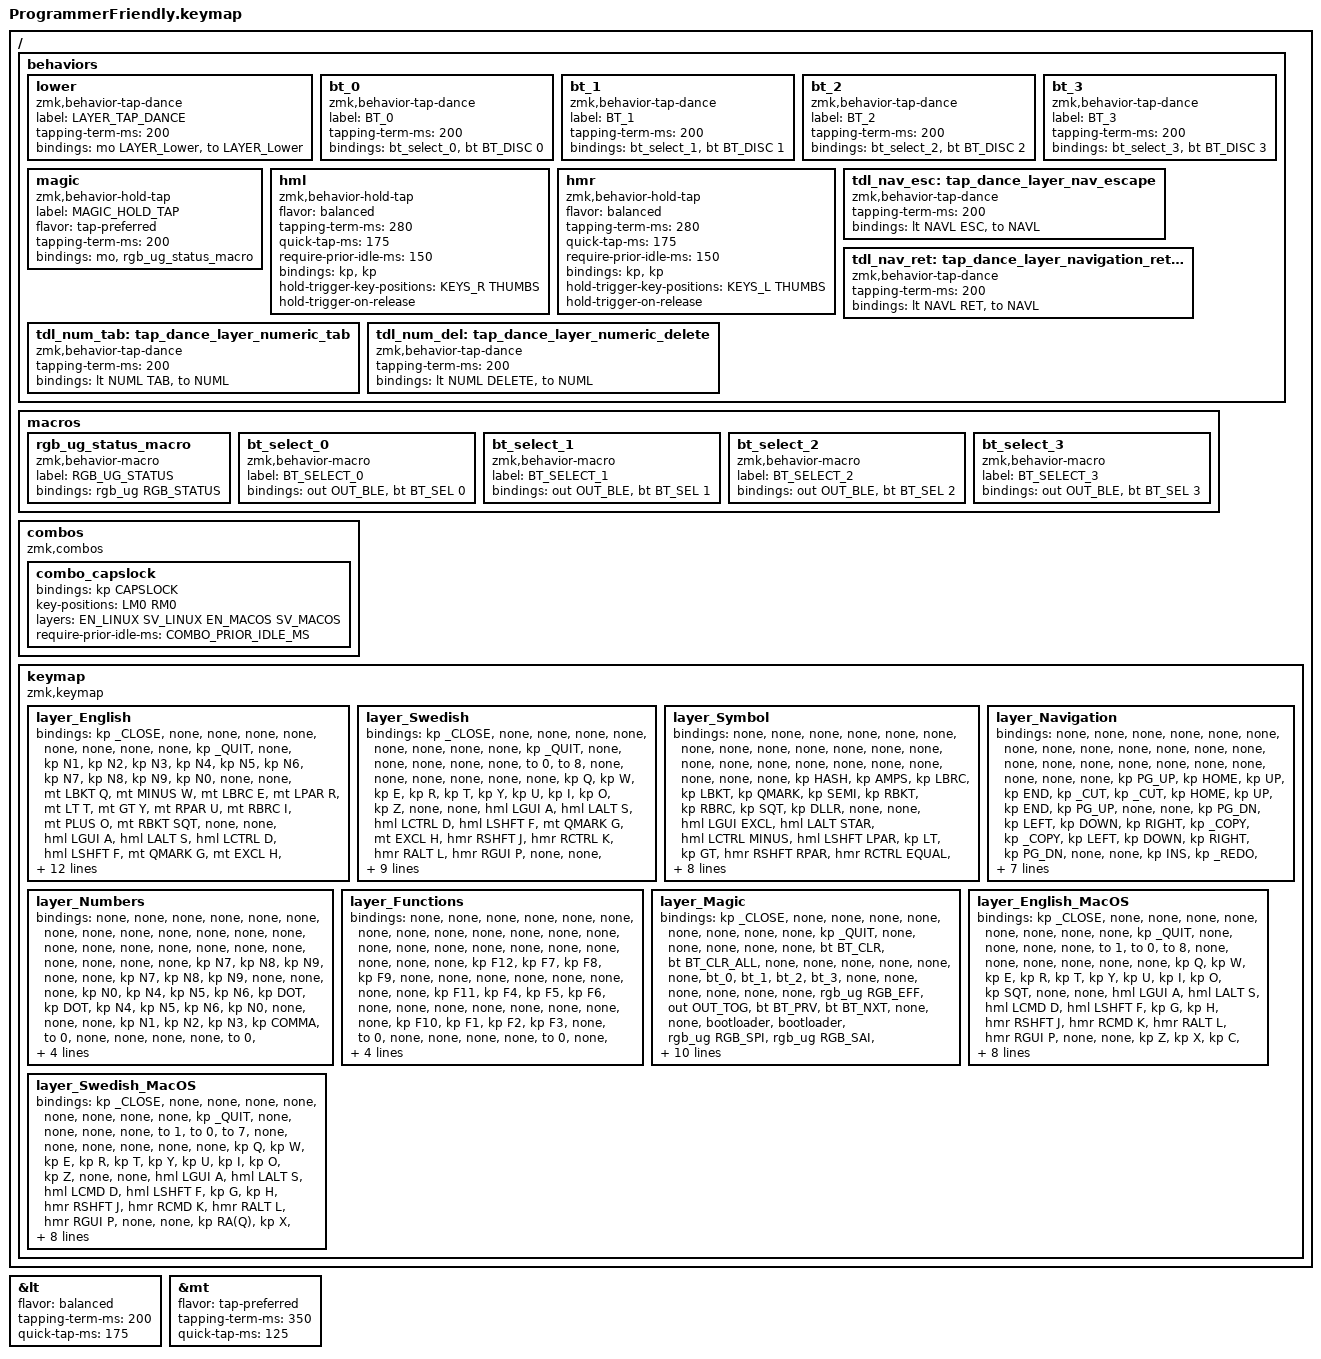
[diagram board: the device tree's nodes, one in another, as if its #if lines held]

/*
 * Copyright (c) 2020 The ZMK Contributors
 * Copyright (c) 2023 Innaworks Development Limited, trading as MoErgo
 *
 * SPDX-License-Identifier: MIT
 */


/* THIS FILE WAS GENERATED BY GLOVE80 LAYOUT EDITOR
 *
 * This file was generated automatically. You may or may not want to
 * edit it directly.
 */

#include <behaviors.dtsi>
/* Include all behavior includes needed */
#include <dt-bindings/zmk/outputs.h>
#include <dt-bindings/zmk/keys.h>
#include <dt-bindings/zmk/bt.h>
#include <dt-bindings/zmk/rgb.h>

/* Automatically generated layer name #define */
#define LAYER_English 0
#define LAYER_Swedish 1
#define LAYER_Symbol 2
#define LAYER_Navigation 3
#define LAYER_Numbers 4
#define LAYER_Functions 5
#define LAYER_Magic 6
#define LAYER_English_MacOS 7
#define LAYER_Swedish_MacOS 8

/* To deal with the situation where there is no Lower layer, to keep &lower happy */
#ifndef LAYER_Lower
#define LAYER_Lower 0
#endif

/* Custom Device-tree */



/* Glove80 system behavior & macros */
/ {
    behaviors {
        // For the "layer" key, it'd nice to be able to use it as either a shift or a toggle.
        // Configure it as a tap dance, so the first tap (or hold) is a &mo and the second tap is a &to
        lower: lower {
            compatible = "zmk,behavior-tap-dance";
            label = "LAYER_TAP_DANCE";
            #binding-cells = <0>;
            tapping-term-ms = <200>;
            bindings = <&mo LAYER_Lower>, <&to LAYER_Lower>;
        };
    };
};

/ {
    macros {
        rgb_ug_status_macro: rgb_ug_status_macro {
            label = "RGB_UG_STATUS";
            compatible = "zmk,behavior-macro";
            #binding-cells = <0>;
            bindings
                = <&rgb_ug RGB_STATUS>;
        };
    };
};


/ {
#ifdef BT_DISC_CMD
    behaviors {
        bt_0: bt_0 {
            compatible = "zmk,behavior-tap-dance";
            label = "BT_0";
            #binding-cells = <0>;
            tapping-term-ms = <200>;
            bindings = <&bt_select_0>, <&bt BT_DISC 0>;
        };
        bt_1: bt_1 {
            compatible = "zmk,behavior-tap-dance";
            label = "BT_1";
            #binding-cells = <0>;
            tapping-term-ms = <200>;
            bindings = <&bt_select_1>, <&bt BT_DISC 1>;
        };
        bt_2: bt_2 {
            compatible = "zmk,behavior-tap-dance";
            label = "BT_2";
            #binding-cells = <0>;
            tapping-term-ms = <200>;
            bindings = <&bt_select_2>, <&bt BT_DISC 2>;
        };
        bt_3: bt_3 {
            compatible = "zmk,behavior-tap-dance";
            label = "BT_3";
            #binding-cells = <0>;
            tapping-term-ms = <200>;
            bindings = <&bt_select_3>, <&bt BT_DISC 3>;
        };
    };
    macros {
        bt_select_0: bt_select_0 {
            label = "BT_SELECT_0";
            compatible = "zmk,behavior-macro";
            #binding-cells = <0>;
            bindings
                = <&out OUT_BLE>,
                  <&bt BT_SEL 0>;
        };
        bt_select_1: bt_select_1 {
            label = "BT_SELECT_1";
            compatible = "zmk,behavior-macro";
            #binding-cells = <0>;
            bindings
                = <&out OUT_BLE>,
                  <&bt BT_SEL 1>;
        };
        bt_select_2: bt_select_2 {
            label = "BT_SELECT_2";
            compatible = "zmk,behavior-macro";
            #binding-cells = <0>;
            bindings
                = <&out OUT_BLE>,
                  <&bt BT_SEL 2>;
        };
        bt_select_3: bt_select_3 {
            label = "BT_SELECT_3";
            compatible = "zmk,behavior-macro";
            #binding-cells = <0>;
            bindings
                = <&out OUT_BLE>,
                  <&bt BT_SEL 3>;
        };
    };
#else
    macros {
        bt_0: bt_0 {
            label = "BT_0";
            compatible = "zmk,behavior-macro";
            #binding-cells = <0>;
            bindings
                = <&out OUT_BLE>,
                  <&bt BT_SEL 0>;
        };
        bt_1: bt_1 {
            label = "BT_1";
            compatible = "zmk,behavior-macro";
            #binding-cells = <0>;
            bindings
                = <&out OUT_BLE>,
                  <&bt BT_SEL 1>;
        };
        bt_2: bt_2 {
            label = "BT_2";
            compatible = "zmk,behavior-macro";
            #binding-cells = <0>;
            bindings
                = <&out OUT_BLE>,
                  <&bt BT_SEL 2>;
        };
        bt_3: bt_3 {
            label = "BT_3";
            compatible = "zmk,behavior-macro";
            #binding-cells = <0>;
            bindings
                = <&out OUT_BLE>,
                  <&bt BT_SEL 3>;
        };
    };
#endif
};

/ {
    behaviors {
        magic: magic {
            compatible = "zmk,behavior-hold-tap";
            label = "MAGIC_HOLD_TAP";
            #binding-cells = <2>;
            flavor = "tap-preferred";
            tapping-term-ms = <200>;
            bindings = <&mo>, <&rgb_ug_status_macro>;
        };
    };
};

/* #define for key positions */
#define POS_LH_T1 52
#define POS_LH_T2 53
#define POS_LH_T3 54
#define POS_LH_T4 69
#define POS_LH_T5 70
#define POS_LH_T6 71
#define POS_LH_C1R2 15
#define POS_LH_C1R3 27
#define POS_LH_C1R4 39
#define POS_LH_C1R5 51
#define POS_LH_C2R1 4
#define POS_LH_C2R2 14
#define POS_LH_C2R3 26
#define POS_LH_C2R4 38
#define POS_LH_C2R5 50
#define POS_LH_C2R6 68
#define POS_LH_C3R1 3
#define POS_LH_C3R2 13
#define POS_LH_C3R3 25
#define POS_LH_C3R4 37
#define POS_LH_C3R5 49
#define POS_LH_C3R6 67
#define POS_LH_C4R1 2
#define POS_LH_C4R2 12
#define POS_LH_C4R3 24
#define POS_LH_C4R4 36
#define POS_LH_C4R5 48
#define POS_LH_C4R6 66
#define POS_LH_C5R1 1
#define POS_LH_C5R2 11
#define POS_LH_C5R3 23
#define POS_LH_C5R4 35
#define POS_LH_C5R5 47
#define POS_LH_C5R6 65
#define POS_LH_C6R1 0
#define POS_LH_C6R2 10
#define POS_LH_C6R3 22
#define POS_LH_C6R4 34
#define POS_LH_C6R5 46
#define POS_LH_C6R6 64
#define POS_RH_T1 57
#define POS_RH_T2 56
#define POS_RH_T3 55
#define POS_RH_T4 74
#define POS_RH_T5 73
#define POS_RH_T6 72
#define POS_RH_C1R2 16
#define POS_RH_C1R3 28
#define POS_RH_C1R4 40
#define POS_RH_C1R5 58
#define POS_RH_C2R1 5
#define POS_RH_C2R2 17
#define POS_RH_C2R3 29
#define POS_RH_C2R4 41
#define POS_RH_C2R5 59
#define POS_RH_C2R6 75
#define POS_RH_C3R1 6
#define POS_RH_C3R2 18
#define POS_RH_C3R3 30
#define POS_RH_C3R4 42
#define POS_RH_C3R5 60
#define POS_RH_C3R6 76
#define POS_RH_C4R1 7
#define POS_RH_C4R2 19
#define POS_RH_C4R3 31
#define POS_RH_C4R4 43
#define POS_RH_C4R5 61
#define POS_RH_C4R6 77
#define POS_RH_C5R1 8
#define POS_RH_C5R2 20
#define POS_RH_C5R3 32
#define POS_RH_C5R4 44
#define POS_RH_C5R5 62
#define POS_RH_C5R6 78
#define POS_RH_C6R1 9
#define POS_RH_C6R2 21
#define POS_RH_C6R3 33
#define POS_RH_C6R4 45
#define POS_RH_C6R5 63
#define POS_RH_C6R6 79

/* Custom Defined Behaviors */
/ {
/* GLOVE80 KEY MATRIX / LAYOUT MAPPING
 ╭────────────────────╮       ╭────────────────────╮
 │  0   1   2   3   4 ╰───┬───╯  5   6   7   8   9 │
 │ 10  11  12  13  14  15 │ 16  17  18  19  20  21 │
 │ 22  23  24  25  26  27 │ 28  29  30  31  32  33 │
 │ 34  35  36  37  38  39 │ 40  41  42  43  44  45 │
 │ 46  47  48  49  50  51 │ 58  59  60  61  62  63 │
 │ 64  65  66  67  68 ╭───┴───╮ 75  76  77  78  79 │
 ╰───────────┬────────┴───┬───┴────────┬───────────╯
             │ 52  53  54 │ 55  56  57 │
             │ 69  70  71 │ 72  73  74 │
             ╰────────────┴────────────╯

 ╭────────────────────╮       ╭────────────────────╮
 │ LC5 LC4 LC3 LC2 LC1╰───┬───╯ RC1 RC2 RC3 RC4 RC5│
 │ LN5 LN4 LN3 LN2 LN1 LN0│ RN0 RN1 RN2 RN3 RN4 RN5│
 │ LT5 LT4 LT3 LT2 LT1 LT0│ RT0 RT1 RT2 RT3 RT4 RT5│
 │ LM5 LM4 LM3 LM2 LM1 LM0│ RM0 RM1 RM2 RM3 RM4 RM5│
 │ LB5 LB4 LB3 LB2 LB1 LB0│ RB0 RB1 RB2 RB3 RB4 RB5│
 │ LF5 LF4 LF3 LF2 LF1╭───┴───╮ RF1 RF2 RF3 RF4 RF5│
 ╰───────────┬────────┴───┬───┴────────┬───────────╯
             │ LH5 LH4 LH3│ RH3 RH4 RH5│
             │ LH2 LH1 LH0│ RH0 RH1 RH2│
             ╰────────────┴────────────╯

 C : Ceiling
 N : Number
 T : Top
 M : Middle
 B : Bottom
 F : Floor
*/

#define LC1  4  // left-ceiling row
#define LC2  3
#define LC3  2
#define LC4  1
#define LC5  0

#define RC1  5  // right-ceiling row
#define RC2  6
#define RC3  7
#define RC4  8
#define RC5  9

#define LN0 15  // left-number row
#define LN1 14
#define LN2 13
#define LN3 12
#define LN4 11
#define LN5 10

#define RN0 16  // right-number row
#define RN1 17
#define RN2 18
#define RN3 19
#define RN4 20
#define RN5 21

#define LT0 27  // left-top row
#define LT1 26
#define LT2 25
#define LT3 24
#define LT4 23
#define LT5 22

#define RT0 28  // right-top row
#define RT1 29
#define RT2 30
#define RT3 31
#define RT4 32
#define RT5 33

#define LM0 39  // left-middle row
#define LM1 38
#define LM2 37
#define LM3 36
#define LM4 35
#define LM5 34

#define RM0 40  // right-middle row
#define RM1 41
#define RM2 42
#define RM3 43
#define RM4 44
#define RM5 45

#define LB0 51  // left-bottom row
#define LB1 50
#define LB2 49
#define LB3 48
#define LB4 47
#define LB5 46

#define RB0 58  // right-bottom row
#define RB1 59
#define RB2 60
#define RB3 61
#define RB4 62
#define RB5 63

#define LF1 68  // left-floor row
#define LF2 67
#define LF3 66
#define LF4 65
#define LF5 64

#define RF1 75  // right-floor row
#define RF2 76
#define RF3 77
#define RF4 78
#define RF5 79

#define LH0 71  // left thumb keys
#define LH1 70
#define LH2 69
#define LH3 54
#define LH4 53
#define LH5 52

#define RH0 72  // right thumb keys
#define RH1 73
#define RH2 74
#define RH3 55
#define RH4 56
#define RH5 57

#define KEYS_L              \
    LC5 LC4 LC3 LC2 LC1     \
    LN5 LN4 LN3 LN2 LN1 LN0 \
    LT5 LT4 LT3 LT2 LT1 LT0 \
    LM5 LM4 LM3 LM2 LM1 LM0 \
    LB5 LB4 LB3 LB2 LB1 LB0 \
    LF5 LF4 LF3 LF2 LF1
#define KEYS_R              \
        RC1 RC2 RC3 RC4 RC5 \
    RN0 RN1 RN2 RN3 RN4 RN5 \
    RT0 RT1 RT2 RT3 RT4 RT5 \
    RM0 RM1 RM2 RM3 RM4 RM5 \
    RB0 RB1 RB2 RB3 RB4 RB5 \
        RF1 RF2 RF3 RF4 RF5
#define THUMBS              \
    LH5 LH4 LH3 RH3 RH4 RH5 \
    LH2 LH1 LH0 RH0 RH1 RH2

#define EN_LINUX    0
#define SV_LINUX    1
#define SYML        2 // Symbols
#define NAVL        3 // Navigation
#define NUML        4 // Numeric
#define FUNL        5 // Functions
#define SYSL        6 // System/Settings
#define EN_MACOS    7
#define SV_MACOS    8

#define OS_MAC   1
#define OS_WIN   2
#define OS_LINUX 3

#define TARGET_OS OS_LINUX

#if TARGET_OS == OS_MAC
#   define _C LG
#   define _QUIT _C(Q)
#   define _APP_NXT LG(TAB)
#   define _APP_PRV LS(LG(TAB))
#   define _WIN_NXT LG(GRAVE)
#   define _WIN_PRV LS(LG(GRAVE))
#   define _LOCK_SCR   LC(LG(Q))
#else
#   define _C LC
#   define _QUIT LA(F4)
#   define _APP_NXT LA(TAB)
#   define _APP_PRV LS(LA(TAB))
#   define _WIN_NXT LC(TAB)
#   define _WIN_PRV LS(LC(TAB))
#   define _LOCK_SCR LC(LG(Q))
#endif

#define _CUT        _C(X)
#define _COPY       _C(C)
#define _PASTE      _C(V)
#define _UNDO       _C(Z)
#define _REDO       LS(_UNDO)
#define _SEL_ALL    _C(A)
#define _CLOSE      _C(W)


/*HACK*/};
&lt {
    flavor = "balanced";
    tapping-term-ms = <200>;
    quick-tap-ms = <175>;                // repeat on tap-into-hold
    //require-prior-idle-ms = <150>;
};

/* Override the default &mt settings to enable fast typing. Note that this config will cause unexpected behavior in other functionality that relies on the default &mt implementation.*/
&mt {
    flavor = "tap-preferred"; // the default is "hold-preferred", which is the exact opposite.
    tapping-term-ms = <350>;
    quick-tap-ms = <125>;
};
/*HACK*//{

behaviors {
    // left-hand HRMs
    hml: hml {
        compatible = "zmk,behavior-hold-tap";
        #binding-cells = <2>;
        flavor = "balanced";
        tapping-term-ms = <280>;
        quick-tap-ms = <175>;                // repeat on tap-into-hold
        require-prior-idle-ms = <150>;
        bindings = <&kp>, <&kp>;
        hold-trigger-key-positions = <KEYS_R THUMBS>;
        hold-trigger-on-release;             // delay positional check until key-release
    };

    // right-hand HRMs
    hmr: hmr {
        compatible = "zmk,behavior-hold-tap";
        #binding-cells = <2>;
        flavor = "balanced";
        tapping-term-ms = <280>;
        quick-tap-ms = <175>;                // repeat on tap-into-hold
        require-prior-idle-ms = <150>;
        bindings = <&kp>, <&kp>;
        hold-trigger-key-positions = <KEYS_L THUMBS>;
        hold-trigger-on-release;             // delay positional check until key-release
    };

    // Tap-dance and layer tap: one tap outputs a key press, two taps switches to layer, tap and hold enables the layer temporarily.
    tdl_nav_esc: tap_dance_layer_nav_escape {
        compatible = "zmk,behavior-tap-dance";
        #binding-cells = <0>;
        tapping-term-ms = <200>;
        bindings = <&lt NAVL ESC>, <&to NAVL>;
    };
    tdl_nav_ret: tap_dance_layer_navigation_return {
        compatible = "zmk,behavior-tap-dance";
        #binding-cells = <0>;
        tapping-term-ms = <200>;
        bindings = <&lt NAVL RET>, <&to NAVL>;
    };
    tdl_num_tab: tap_dance_layer_numeric_tab {
        compatible = "zmk,behavior-tap-dance";
        #binding-cells = <0>;
        tapping-term-ms = <200>;
        bindings = <&lt NUML TAB>, <&to NUML>;
    };
    tdl_num_del: tap_dance_layer_numeric_delete {
        compatible = "zmk,behavior-tap-dance";
        #binding-cells = <0>;
        tapping-term-ms = <200>;
        bindings = <&lt NUML DELETE>, <&to NUML>;
    };
};

#define COMBO_PRIOR_IDLE_MS 150
#define COMBO_TIMEOUT_MS 10

combos {
    compatible = "zmk,combos";

    // Both hand combos
    combo_capslock { // G + H -> Caps Lock
        bindings = <&kp CAPSLOCK>;
        key-positions = <LM0 RM0>;
        layers = <EN_LINUX SV_LINUX EN_MACOS SV_MACOS>;
        require-prior-idle-ms = <COMBO_PRIOR_IDLE_MS>;
        //timeout-ms = <COMBO_TIMEOUT_MS>;
    };
};
};

/* Automatically generated macro definitions */
/ {
    macros {
    
    };
};

/* Automatically generated keymap */
/ {
    keymap {
        compatible = "zmk,keymap";


        layer_English {
            bindings = <
              // Row 1 Left
              /* F1    */ &kp _CLOSE
              /* F2    */ &none
              /* F3    */ &none
              /* F4    */ &none
              /* F5    */ &none
              // Row 1 Right
              /* F6    */ &none
              /* F7    */ &none
              /* F8    */ &none
              /* F9    */ &none
              /* F10   */ &kp _QUIT
              // Row 2 Left
              /* EQUAL */ &none
              /* 1     */ &kp N1
              /* 2     */ &kp N2
              /* 3     */ &kp N3
              /* 4     */ &kp N4
              /* 5     */ &kp N5
              // Row 2 Right
              /* 6     */ &kp N6
              /* 7     */ &kp N7
              /* 8     */ &kp N8
              /* 9     */ &kp N9
              /* 0     */ &kp N0
              /* MINUS */ &none
              // Row 3 Left
              /* TAB   */ &none
              /* Q     */ &mt LBKT Q
              /* W     */ &mt MINUS W
              /* E     */ &mt LBRC E
              /* R     */ &mt LPAR R
              /* T     */ &mt LT T
              // Row 3 Right
              /* Y     */ &mt GT Y
              /* U     */ &mt RPAR U
              /* I     */ &mt RBRC I
              /* O     */ &mt PLUS O
              /* P     */ &mt RBKT SQT
              /* BSLSH */ &none
              // Row 4 Left
              /* ESC   */ &none
              /* A     */ &hml LGUI A
              /* S     */ &hml LALT S
              /* D     */ &hml LCTRL D
              /* F     */ &hml LSHFT F
              /* G     */ &mt QMARK G
              // Row 4 Right
              /* H     */ &mt EXCL H
              /* J     */ &hmr RSHFT J
              /* K     */ &hmr RCTRL K
              /* L     */ &hmr RALT L
              /* SEMI  */ &hmr RGUI P
              /* SQUOT */ &none
              // Row 5 Left
              /* BQUOT */ &none
              /* Z     */ &mt STAR Z
              /* X     */ &mt UNDER X
              /* C     */ &mt AT C
              /* V     */ &mt EQUAL V
              /* B     */ &mt PIPE B
              // Row 5 Thumb
              /* LSHFT */ &tdl_num_del
              /* LCTRL */ &kp C_PREV
              /* LOWER */ &kp C_NEXT
              /* LGUI  */ &kp C_VOL_DN
              /* RCTRL */ &lt 5 C_VOL_UP
              /* RSHFT */ &tdl_num_tab
              // Row 5 Right
              /* N     */ &mt AMPS N
              /* M     */ &mt DQT M
              /* COMMA */ &mt SEMI COMMA
              /* DOT   */ &mt COLON DOT
              /* FSLSH */ &mt BSLH FSLH
              /* PGUP  */ &none
              // Row 6 Left
              /* MAGIC */ &magic LAYER_Magic 0
              /* HOME  */ &to 1
              /* END   */ &kp LGUI
              /* LEFT  */ &kp LALT
              /* RIGHT */ &kp LSHFT
              // Row 6 Thumb
              /* BKSP  */ &lt 2 BSPC
              /* DEL   */ &tdl_nav_esc
              /* LALT  */ &kp C_PP
              /* RALT  */ &kp C_MUTE
              /* ENTER */ &tdl_nav_ret
              /* SPACE */ &lt 2 SPACE
              // Row 6 Right
              /* UP    */ &kp RSHFT
              /* DOWN  */ &kp RALT
              /* LBRKT */ &kp RGUI
              /* RBRKT */ &to 7
              /* PGDN  */ &magic LAYER_Magic 0
            >;
        };

        layer_Swedish {
            bindings = <
              // Row 1 Left
              /* F1    */ &kp _CLOSE
              /* F2    */ &none
              /* F3    */ &none
              /* F4    */ &none
              /* F5    */ &none
              // Row 1 Right
              /* F6    */ &none
              /* F7    */ &none
              /* F8    */ &none
              /* F9    */ &none
              /* F10   */ &kp _QUIT
              // Row 2 Left
              /* EQUAL */ &none
              /* 1     */ &none
              /* 2     */ &none
              /* 3     */ &none
              /* 4     */ &none
              /* 5     */ &to 0
              // Row 2 Right
              /* 6     */ &to 8
              /* 7     */ &none
              /* 8     */ &none
              /* 9     */ &none
              /* 0     */ &none
              /* MINUS */ &none
              // Row 3 Left
              /* TAB   */ &none
              /* Q     */ &kp Q
              /* W     */ &kp W
              /* E     */ &kp E
              /* R     */ &kp R
              /* T     */ &kp T
              // Row 3 Right
              /* Y     */ &kp Y
              /* U     */ &kp U
              /* I     */ &kp I
              /* O     */ &kp O
              /* P     */ &kp Z
              /* BSLSH */ &none
              // Row 4 Left
              /* ESC   */ &none
              /* A     */ &hml LGUI A
              /* S     */ &hml LALT S
              /* D     */ &hml LCTRL D
              /* F     */ &hml LSHFT F
              /* G     */ &mt QMARK G
              // Row 4 Right
              /* H     */ &mt EXCL H
              /* J     */ &hmr RSHFT J
              /* K     */ &hmr RCTRL K
              /* L     */ &hmr RALT L
              /* SEMI  */ &hmr RGUI P
              /* SQUOT */ &none
              // Row 5 Left
              /* BQUOT */ &none
              /* Z     */ &kp RA(Q)
              /* X     */ &kp X
              /* C     */ &kp C
              /* V     */ &kp V
              /* B     */ &kp B
              // Row 5 Thumb
              /* LSHFT */ &tdl_num_del
              /* LCTRL */ &kp C_PREV
              /* LOWER */ &kp C_NEXT
              /* LGUI  */ &kp C_VOL_DN
              /* RCTRL */ &lt 5 C_VOL_UP
              /* RSHFT */ &tdl_num_tab
              // Row 5 Right
              /* N     */ &kp N
              /* M     */ &mt DQT M
              /* COMMA */ &kp COMMA
              /* DOT   */ &kp DOT
              /* FSLSH */ &kp RA(P)
              /* PGUP  */ &none
              // Row 6 Left
              /* MAGIC */ &magic LAYER_Magic 0
              /* HOME  */ &none
              /* END   */ &kp LGUI
              /* LEFT  */ &kp LALT
              /* RIGHT */ &kp LSHFT
              // Row 6 Thumb
              /* BKSP  */ &lt 2 BSPC
              /* DEL   */ &tdl_nav_esc
              /* LALT  */ &kp C_PP
              /* RALT  */ &kp C_MUTE
              /* ENTER */ &tdl_nav_ret
              /* SPACE */ &lt 2 SPACE
              // Row 6 Right
              /* UP    */ &kp RSHFT
              /* DOWN  */ &kp RALT
              /* LBRKT */ &kp RGUI
              /* RBRKT */ &none
              /* PGDN  */ &magic LAYER_Magic 0
            >;
        };

        layer_Symbol {
            bindings = <
              // Row 1 Left
              /* F1    */ &none
              /* F2    */ &none
              /* F3    */ &none
              /* F4    */ &none
              /* F5    */ &none
              // Row 1 Right
              /* F6    */ &none
              /* F7    */ &none
              /* F8    */ &none
              /* F9    */ &none
              /* F10   */ &none
              // Row 2 Left
              /* EQUAL */ &none
              /* 1     */ &none
              /* 2     */ &none
              /* 3     */ &none
              /* 4     */ &none
              /* 5     */ &none
              // Row 2 Right
              /* 6     */ &none
              /* 7     */ &none
              /* 8     */ &none
              /* 9     */ &none
              /* 0     */ &none
              /* MINUS */ &none
              // Row 3 Left
              /* TAB   */ &none
              /* Q     */ &kp HASH
              /* W     */ &kp AMPS
              /* E     */ &kp LBRC
              /* R     */ &kp LBKT
              /* T     */ &kp QMARK
              // Row 3 Right
              /* Y     */ &kp SEMI
              /* U     */ &kp RBKT
              /* I     */ &kp RBRC
              /* O     */ &kp SQT
              /* P     */ &kp DLLR
              /* BSLSH */ &none
              // Row 4 Left
              /* ESC   */ &none
              /* A     */ &hml LGUI EXCL
              /* S     */ &hml LALT STAR
              /* D     */ &hml LCTRL MINUS
              /* F     */ &hml LSHFT LPAR
              /* G     */ &kp LT
              // Row 4 Right
              /* H     */ &kp GT
              /* J     */ &hmr RSHFT RPAR
              /* K     */ &hmr RCTRL EQUAL
              /* L     */ &hmr RALT DOUBLE_QUOTES
              /* SEMI  */ &hmr RGUI SLASH
              /* SQUOT */ &none
              // Row 5 Left
              /* BQUOT */ &none
              /* Z     */ &kp TILDE
              /* X     */ &kp PRCNT
              /* C     */ &kp PLUS
              /* V     */ &kp PIPE
              /* B     */ &kp COLON
              // Row 5 Thumb
              /* LSHFT */ &kp LALT
              /* LCTRL */ &none
              /* LOWER */ &none
              /* LGUI  */ &none
              /* RCTRL */ &none
              /* RSHFT */ &kp RALT
              // Row 5 Right
              /* N     */ &kp QMARK
              /* M     */ &kp UNDER
              /* COMMA */ &kp AT
              /* DOT   */ &kp GRAVE
              /* FSLSH */ &kp BSLH
              /* PGUP  */ &none
              // Row 6 Left
              /* MAGIC */ &magic LAYER_Magic 0
              /* HOME  */ &none
              /* END   */ &none
              /* LEFT  */ &none
              /* RIGHT */ &none
              // Row 6 Thumb
              /* BKSP  */ &to 0
              /* DEL   */ &none
              /* LALT  */ &none
              /* RALT  */ &none
              /* ENTER */ &none
              /* SPACE */ &to 0
              // Row 6 Right
              /* UP    */ &none
              /* DOWN  */ &none
              /* LBRKT */ &none
              /* RBRKT */ &none
              /* PGDN  */ &none
            >;
        };

        layer_Navigation {
            bindings = <
              // Row 1 Left
              /* F1    */ &none
              /* F2    */ &none
              /* F3    */ &none
              /* F4    */ &none
              /* F5    */ &none
              // Row 1 Right
              /* F6    */ &none
              /* F7    */ &none
              /* F8    */ &none
              /* F9    */ &none
              /* F10   */ &none
              // Row 2 Left
              /* EQUAL */ &none
              /* 1     */ &none
              /* 2     */ &none
              /* 3     */ &none
              /* 4     */ &none
              /* 5     */ &none
              // Row 2 Right
              /* 6     */ &none
              /* 7     */ &none
              /* 8     */ &none
              /* 9     */ &none
              /* 0     */ &none
              /* MINUS */ &none
              // Row 3 Left
              /* TAB   */ &none
              /* Q     */ &kp PG_UP
              /* W     */ &kp HOME
              /* E     */ &kp UP
              /* R     */ &kp END
              /* T     */ &kp _CUT
              // Row 3 Right
              /* Y     */ &kp _CUT
              /* U     */ &kp HOME
              /* I     */ &kp UP
              /* O     */ &kp END
              /* P     */ &kp PG_UP
              /* BSLSH */ &none
              // Row 4 Left
              /* ESC   */ &none
              /* A     */ &kp PG_DN
              /* S     */ &kp LEFT
              /* D     */ &kp DOWN
              /* F     */ &kp RIGHT
              /* G     */ &kp _COPY
              // Row 4 Right
              /* H     */ &kp _COPY
              /* J     */ &kp LEFT
              /* K     */ &kp DOWN
              /* L     */ &kp RIGHT
              /* SEMI  */ &kp PG_DN
              /* SQUOT */ &none
              // Row 5 Left
              /* BQUOT */ &none
              /* Z     */ &kp INS
              /* X     */ &kp _REDO
              /* C     */ &kp _SEL_ALL
              /* V     */ &kp _UNDO
              /* B     */ &kp _PASTE
              // Row 5 Thumb
              /* LSHFT */ &to 0
              /* LCTRL */ &none
              /* LOWER */ &none
              /* LGUI  */ &none
              /* RCTRL */ &none
              /* RSHFT */ &to 0
              // Row 5 Right
              /* N     */ &kp _PASTE
              /* M     */ &kp _UNDO
              /* COMMA */ &kp _REDO
              /* DOT   */ &kp _SEL_ALL
              /* FSLSH */ &kp INS
              /* PGUP  */ &none
              // Row 6 Left
              /* MAGIC */ &magic LAYER_Magic 0
              /* HOME  */ &none
              /* END   */ &none
              /* LEFT  */ &kp _WIN_PRV
              /* RIGHT */ &kp _WIN_NXT
              // Row 6 Thumb
              /* BKSP  */ &to 1
              /* DEL   */ &none
              /* LALT  */ &none
              /* RALT  */ &none
              /* ENTER */ &none
              /* SPACE */ &to 1
              // Row 6 Right
              /* UP    */ &kp _APP_PRV
              /* DOWN  */ &kp _APP_NXT
              /* LBRKT */ &none
              /* RBRKT */ &none
              /* PGDN  */ &none
            >;
        };

        layer_Numbers {
            bindings = <
              // Row 1 Left
              /* F1    */ &none
              /* F2    */ &none
              /* F3    */ &none
              /* F4    */ &none
              /* F5    */ &none
              // Row 1 Right
              /* F6    */ &none
              /* F7    */ &none
              /* F8    */ &none
              /* F9    */ &none
              /* F10   */ &none
              // Row 2 Left
              /* EQUAL */ &none
              /* 1     */ &none
              /* 2     */ &none
              /* 3     */ &none
              /* 4     */ &none
              /* 5     */ &none
              // Row 2 Right
              /* 6     */ &none
              /* 7     */ &none
              /* 8     */ &none
              /* 9     */ &none
              /* 0     */ &none
              /* MINUS */ &none
              // Row 3 Left
              /* TAB   */ &none
              /* Q     */ &none
              /* W     */ &kp N7
              /* E     */ &kp N8
              /* R     */ &kp N9
              /* T     */ &none
              // Row 3 Right
              /* Y     */ &none
              /* U     */ &kp N7
              /* I     */ &kp N8
              /* O     */ &kp N9
              /* P     */ &none
              /* BSLSH */ &none
              // Row 4 Left
              /* ESC   */ &none
              /* A     */ &kp N0
              /* S     */ &kp N4
              /* D     */ &kp N5
              /* F     */ &kp N6
              /* G     */ &kp DOT
              // Row 4 Right
              /* H     */ &kp DOT
              /* J     */ &kp N4
              /* K     */ &kp N5
              /* L     */ &kp N6
              /* SEMI  */ &kp N0
              /* SQUOT */ &none
              // Row 5 Left
              /* BQUOT */ &none
              /* Z     */ &none
              /* X     */ &kp N1
              /* C     */ &kp N2
              /* V     */ &kp N3
              /* B     */ &kp COMMA
              // Row 5 Thumb
              /* LSHFT */ &to 0
              /* LCTRL */ &none
              /* LOWER */ &none
              /* LGUI  */ &none
              /* RCTRL */ &none
              /* RSHFT */ &to 0
              // Row 5 Right
              /* N     */ &kp COMMA
              /* M     */ &kp N1
              /* COMMA */ &kp N2
              /* DOT   */ &kp N3
              /* FSLSH */ &none
              /* PGUP  */ &none
              // Row 6 Left
              /* MAGIC */ &magic LAYER_Magic 0
              /* HOME  */ &none
              /* END   */ &none
              /* LEFT  */ &none
              /* RIGHT */ &none
              // Row 6 Thumb
              /* BKSP  */ &to 1
              /* DEL   */ &none
              /* LALT  */ &none
              /* RALT  */ &none
              /* ENTER */ &none
              /* SPACE */ &to 1
              // Row 6 Right
              /* UP    */ &none
              /* DOWN  */ &none
              /* LBRKT */ &none
              /* RBRKT */ &none
              /* PGDN  */ &none
            >;
        };

        layer_Functions {
            bindings = <
              // Row 1 Left
              /* F1    */ &none
              /* F2    */ &none
              /* F3    */ &none
              /* F4    */ &none
              /* F5    */ &none
              // Row 1 Right
              /* F6    */ &none
              /* F7    */ &none
              /* F8    */ &none
              /* F9    */ &none
              /* F10   */ &none
              // Row 2 Left
              /* EQUAL */ &none
              /* 1     */ &none
              /* 2     */ &none
              /* 3     */ &none
              /* 4     */ &none
              /* 5     */ &none
              // Row 2 Right
              /* 6     */ &none
              /* 7     */ &none
              /* 8     */ &none
              /* 9     */ &none
              /* 0     */ &none
              /* MINUS */ &none
              // Row 3 Left
              /* TAB   */ &none
              /* Q     */ &kp F12
              /* W     */ &kp F7
              /* E     */ &kp F8
              /* R     */ &kp F9
              /* T     */ &none
              // Row 3 Right
              /* Y     */ &none
              /* U     */ &none
              /* I     */ &none
              /* O     */ &none
              /* P     */ &none
              /* BSLSH */ &none
              // Row 4 Left
              /* ESC   */ &none
              /* A     */ &kp F11
              /* S     */ &kp F4
              /* D     */ &kp F5
              /* F     */ &kp F6
              /* G     */ &none
              // Row 4 Right
              /* H     */ &none
              /* J     */ &none
              /* K     */ &none
              /* L     */ &none
              /* SEMI  */ &none
              /* SQUOT */ &none
              // Row 5 Left
              /* BQUOT */ &none
              /* Z     */ &kp F10
              /* X     */ &kp F1
              /* C     */ &kp F2
              /* V     */ &kp F3
              /* B     */ &none
              // Row 5 Thumb
              /* LSHFT */ &to 0
              /* LCTRL */ &none
              /* LOWER */ &none
              /* LGUI  */ &none
              /* RCTRL */ &none
              /* RSHFT */ &to 0
              // Row 5 Right
              /* N     */ &none
              /* M     */ &none
              /* COMMA */ &none
              /* DOT   */ &none
              /* FSLSH */ &none
              /* PGUP  */ &none
              // Row 6 Left
              /* MAGIC */ &magic LAYER_Magic 0
              /* HOME  */ &none
              /* END   */ &none
              /* LEFT  */ &none
              /* RIGHT */ &none
              // Row 6 Thumb
              /* BKSP  */ &to 1
              /* DEL   */ &none
              /* LALT  */ &none
              /* RALT  */ &none
              /* ENTER */ &none
              /* SPACE */ &to 1
              // Row 6 Right
              /* UP    */ &none
              /* DOWN  */ &none
              /* LBRKT */ &none
              /* RBRKT */ &none
              /* PGDN  */ &none
            >;
        };

        layer_Magic {
            bindings = <
              // Row 1 Left
              /* F1    */ &kp _CLOSE
              /* F2    */ &none
              /* F3    */ &none
              /* F4    */ &none
              /* F5    */ &none
              // Row 1 Right
              /* F6    */ &none
              /* F7    */ &none
              /* F8    */ &none
              /* F9    */ &none
              /* F10   */ &kp _QUIT
              // Row 2 Left
              /* EQUAL */ &none
              /* 1     */ &none
              /* 2     */ &none
              /* 3     */ &none
              /* 4     */ &none
              /* 5     */ &bt BT_CLR
              // Row 2 Right
              /* 6     */ &bt BT_CLR_ALL
              /* 7     */ &none
              /* 8     */ &none
              /* 9     */ &none
              /* 0     */ &none
              /* MINUS */ &none
              // Row 3 Left
              /* TAB   */ &none
              /* Q     */ &bt_0
              /* W     */ &bt_1
              /* E     */ &bt_2
              /* R     */ &bt_3
              /* T     */ &none
              // Row 3 Right
              /* Y     */ &none
              /* U     */ &none
              /* I     */ &none
              /* O     */ &none
              /* P     */ &none
              /* BSLSH */ &rgb_ug RGB_EFF
              // Row 4 Left
              /* ESC   */ &out OUT_TOG
              /* A     */ &bt BT_PRV
              /* S     */ &bt BT_NXT
              /* D     */ &none
              /* F     */ &none
              /* G     */ &bootloader
              // Row 4 Right
              /* H     */ &bootloader
              /* J     */ &rgb_ug RGB_SPI
              /* K     */ &rgb_ug RGB_SAI
              /* L     */ &rgb_ug RGB_HUI
              /* SEMI  */ &rgb_ug RGB_BRI
              /* SQUOT */ &rgb_ug RGB_TOG
              // Row 5 Left
              /* BQUOT */ &none
              /* Z     */ &none
              /* X     */ &none
              /* C     */ &none
              /* V     */ &none
              /* B     */ &sys_reset
              // Row 5 Thumb
              /* LSHFT */ &bt_2
              /* LCTRL */ &bt_3
              /* LOWER */ &none
              /* LGUI  */ &kp C_VOL_DN
              /* RCTRL */ &kp C_VOL_UP
              /* RSHFT */ &kp C_MUTE
              // Row 5 Right
              /* N     */ &sys_reset
              /* M     */ &rgb_ug RGB_SPD
              /* COMMA */ &rgb_ug RGB_SAD
              /* DOT   */ &rgb_ug RGB_HUD
              /* FSLSH */ &rgb_ug RGB_BRD
              /* PGUP  */ &rgb_ug RGB_EFR
              // Row 6 Left
              /* MAGIC */ &none
              /* HOME  */ &none
              /* END   */ &none
              /* LEFT  */ &none
              /* RIGHT */ &none
              // Row 6 Thumb
              /* BKSP  */ &bt_0
              /* DEL   */ &bt_1
              /* LALT  */ &out OUT_USB
              /* RALT  */ &kp C_PREV
              /* ENTER */ &kp C_NEXT
              /* SPACE */ &kp C_PP
              // Row 6 Right
              /* UP    */ &none
              /* DOWN  */ &none
              /* LBRKT */ &none
              /* RBRKT */ &none
              /* PGDN  */ &none
            >;
        };

        layer_English_MacOS {
            bindings = <
              // Row 1 Left
              /* F1    */ &kp _CLOSE
              /* F2    */ &none
              /* F3    */ &none
              /* F4    */ &none
              /* F5    */ &none
              // Row 1 Right
              /* F6    */ &none
              /* F7    */ &none
              /* F8    */ &none
              /* F9    */ &none
              /* F10   */ &kp _QUIT
              // Row 2 Left
              /* EQUAL */ &none
              /* 1     */ &none
              /* 2     */ &none
              /* 3     */ &none
              /* 4     */ &to 1
              /* 5     */ &to 0
              // Row 2 Right
              /* 6     */ &to 8
              /* 7     */ &none
              /* 8     */ &none
              /* 9     */ &none
              /* 0     */ &none
              /* MINUS */ &none
              // Row 3 Left
              /* TAB   */ &none
              /* Q     */ &kp Q
              /* W     */ &kp W
              /* E     */ &kp E
              /* R     */ &kp R
              /* T     */ &kp T
              // Row 3 Right
              /* Y     */ &kp Y
              /* U     */ &kp U
              /* I     */ &kp I
              /* O     */ &kp O
              /* P     */ &kp SQT
              /* BSLSH */ &none
              // Row 4 Left
              /* ESC   */ &none
              /* A     */ &hml LGUI A
              /* S     */ &hml LALT S
              /* D     */ &hml LCMD D
              /* F     */ &hml LSHFT F
              /* G     */ &kp G
              // Row 4 Right
              /* H     */ &kp H
              /* J     */ &hmr RSHFT J
              /* K     */ &hmr RCMD K
              /* L     */ &hmr RALT L
              /* SEMI  */ &hmr RGUI P
              /* SQUOT */ &none
              // Row 5 Left
              /* BQUOT */ &none
              /* Z     */ &kp Z
              /* X     */ &kp X
              /* C     */ &kp C
              /* V     */ &kp V
              /* B     */ &kp B
              // Row 5 Thumb
              /* LSHFT */ &tdl_num_del
              /* LCTRL */ &kp C_PREV
              /* LOWER */ &kp C_NEXT
              /* LGUI  */ &kp C_VOL_DN
              /* RCTRL */ &lt 5 C_VOL_UP
              /* RSHFT */ &tdl_num_tab
              // Row 5 Right
              /* N     */ &kp N
              /* M     */ &kp M
              /* COMMA */ &kp COMMA
              /* DOT   */ &kp DOT
              /* FSLSH */ &kp FSLH
              /* PGUP  */ &none
              // Row 6 Left
              /* MAGIC */ &magic LAYER_Magic 0
              /* HOME  */ &none
              /* END   */ &kp LGUI
              /* LEFT  */ &kp LALT
              /* RIGHT */ &kp LSHFT
              // Row 6 Thumb
              /* BKSP  */ &lt 2 BSPC
              /* DEL   */ &tdl_nav_esc
              /* LALT  */ &kp C_PP
              /* RALT  */ &kp C_MUTE
              /* ENTER */ &tdl_nav_ret
              /* SPACE */ &lt 2 SPACE
              // Row 6 Right
              /* UP    */ &kp RSHFT
              /* DOWN  */ &kp RALT
              /* LBRKT */ &kp RGUI
              /* RBRKT */ &none
              /* PGDN  */ &magic LAYER_Magic 0
            >;
        };

        layer_Swedish_MacOS {
            bindings = <
              // Row 1 Left
              /* F1    */ &kp _CLOSE
              /* F2    */ &none
              /* F3    */ &none
              /* F4    */ &none
              /* F5    */ &none
              // Row 1 Right
              /* F6    */ &none
              /* F7    */ &none
              /* F8    */ &none
              /* F9    */ &none
              /* F10   */ &kp _QUIT
              // Row 2 Left
              /* EQUAL */ &none
              /* 1     */ &none
              /* 2     */ &none
              /* 3     */ &none
              /* 4     */ &to 1
              /* 5     */ &to 0
              // Row 2 Right
              /* 6     */ &to 7
              /* 7     */ &none
              /* 8     */ &none
              /* 9     */ &none
              /* 0     */ &none
              /* MINUS */ &none
              // Row 3 Left
              /* TAB   */ &none
              /* Q     */ &kp Q
              /* W     */ &kp W
              /* E     */ &kp E
              /* R     */ &kp R
              /* T     */ &kp T
              // Row 3 Right
              /* Y     */ &kp Y
              /* U     */ &kp U
              /* I     */ &kp I
              /* O     */ &kp O
              /* P     */ &kp Z
              /* BSLSH */ &none
              // Row 4 Left
              /* ESC   */ &none
              /* A     */ &hml LGUI A
              /* S     */ &hml LALT S
              /* D     */ &hml LCMD D
              /* F     */ &hml LSHFT F
              /* G     */ &kp G
              // Row 4 Right
              /* H     */ &kp H
              /* J     */ &hmr RSHFT J
              /* K     */ &hmr RCMD K
              /* L     */ &hmr RALT L
              /* SEMI  */ &hmr RGUI P
              /* SQUOT */ &none
              // Row 5 Left
              /* BQUOT */ &none
              /* Z     */ &kp RA(Q)
              /* X     */ &kp X
              /* C     */ &kp C
              /* V     */ &kp V
              /* B     */ &kp B
              // Row 5 Thumb
              /* LSHFT */ &tdl_num_del
              /* LCTRL */ &kp C_PREV
              /* LOWER */ &kp C_NEXT
              /* LGUI  */ &kp C_VOL_DN
              /* RCTRL */ &lt 5 C_VOL_UP
              /* RSHFT */ &tdl_num_tab
              // Row 5 Right
              /* N     */ &kp N
              /* M     */ &kp M
              /* COMMA */ &kp COMMA
              /* DOT   */ &kp DOT
              /* FSLSH */ &kp RA(P)
              /* PGUP  */ &none
              // Row 6 Left
              /* MAGIC */ &magic LAYER_Magic 0
              /* HOME  */ &none
              /* END   */ &kp LGUI
              /* LEFT  */ &kp LALT
              /* RIGHT */ &kp LSHFT
              // Row 6 Thumb
              /* BKSP  */ &lt 2 BSPC
              /* DEL   */ &tdl_nav_esc
              /* LALT  */ &kp C_PP
              /* RALT  */ &kp C_MUTE
              /* ENTER */ &tdl_nav_ret
              /* SPACE */ &lt 2 SPACE
              // Row 6 Right
              /* UP    */ &kp RSHFT
              /* DOWN  */ &kp RALT
              /* LBRKT */ &kp RGUI
              /* RBRKT */ &none
              /* PGDN  */ &magic LAYER_Magic 0
            >;
        };

    };
};
